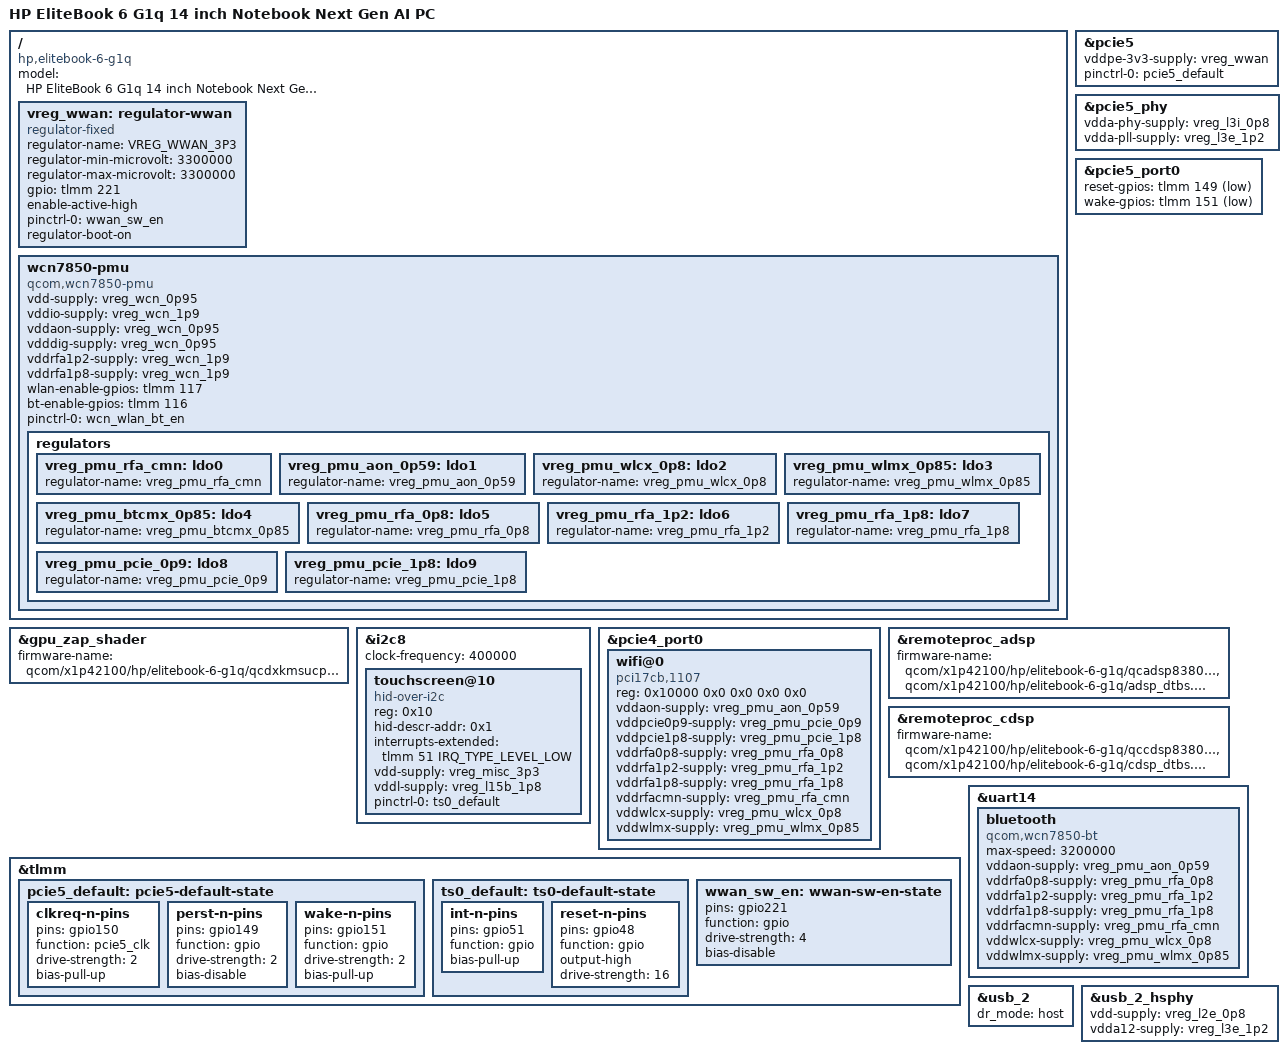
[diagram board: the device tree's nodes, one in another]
// SPDX-License-Identifier: BSD-3-Clause

/dts-v1/;

#include "purwa.dtsi"
#include "hamoa-pmics.dtsi"
#include "x1-hp-elitebook-6-g1q.dtsi"

/delete-node/ &pmc8380_6;
/delete-node/ &pmc8380_6_thermal;
/delete-node/ &pmc8380_6_die_temp;

/ {
	model = "HP EliteBook 6 G1q 14 inch Notebook Next Gen AI PC";
	compatible = "hp,elitebook-6-g1q", "qcom,x1p42100";

	vreg_wwan: regulator-wwan {
		compatible = "regulator-fixed";

		regulator-name = "VREG_WWAN_3P3";
		regulator-min-microvolt = <3300000>;
		regulator-max-microvolt = <3300000>;

		gpio = <&tlmm 221 GPIO_ACTIVE_HIGH>;
		enable-active-high;

		pinctrl-0 = <&wwan_sw_en>;
		pinctrl-names = "default";

		regulator-boot-on;
	};

	wcn7850-pmu {
		compatible = "qcom,wcn7850-pmu";

		vdd-supply = <&vreg_wcn_0p95>;
		vddio-supply = <&vreg_wcn_1p9>;
		vddaon-supply = <&vreg_wcn_0p95>;
		vdddig-supply = <&vreg_wcn_0p95>;
		vddrfa1p2-supply = <&vreg_wcn_1p9>;
		vddrfa1p8-supply = <&vreg_wcn_1p9>;

		wlan-enable-gpios = <&tlmm 117 GPIO_ACTIVE_HIGH>;
		bt-enable-gpios = <&tlmm 116 GPIO_ACTIVE_HIGH>;

		pinctrl-0 = <&wcn_wlan_bt_en>;
		pinctrl-names = "default";

		regulators {
			vreg_pmu_rfa_cmn: ldo0 {
				regulator-name = "vreg_pmu_rfa_cmn";
			};

			vreg_pmu_aon_0p59: ldo1 {
				regulator-name = "vreg_pmu_aon_0p59";
			};

			vreg_pmu_wlcx_0p8: ldo2 {
				regulator-name = "vreg_pmu_wlcx_0p8";
			};

			vreg_pmu_wlmx_0p85: ldo3 {
				regulator-name = "vreg_pmu_wlmx_0p85";
			};

			vreg_pmu_btcmx_0p85: ldo4 {
				regulator-name = "vreg_pmu_btcmx_0p85";
			};

			vreg_pmu_rfa_0p8: ldo5 {
				regulator-name = "vreg_pmu_rfa_0p8";
			};

			vreg_pmu_rfa_1p2: ldo6 {
				regulator-name = "vreg_pmu_rfa_1p2";
			};

			vreg_pmu_rfa_1p8: ldo7 {
				regulator-name = "vreg_pmu_rfa_1p8";
			};

			vreg_pmu_pcie_0p9: ldo8 {
				regulator-name = "vreg_pmu_pcie_0p9";
			};

			vreg_pmu_pcie_1p8: ldo9 {
				regulator-name = "vreg_pmu_pcie_1p8";
			};
		};
	};
};

&gpu_zap_shader {
	firmware-name = "qcom/x1p42100/hp/elitebook-6-g1q/qcdxkmsucpurwa.mbn";
};

&i2c8 {
	clock-frequency = <400000>;

	status = "okay";

	touchscreen@10 {
		compatible = "hid-over-i2c";
		reg = <0x10>;

		hid-descr-addr = <0x1>;
		interrupts-extended = <&tlmm 51 IRQ_TYPE_LEVEL_LOW>;

		vdd-supply = <&vreg_misc_3p3>;
		vddl-supply = <&vreg_l15b_1p8>;

		pinctrl-0 = <&ts0_default>;
		pinctrl-names = "default";
	};
};

&pcie4_port0 {
	wifi@0 {
		compatible = "pci17cb,1107";
		reg = <0x10000 0x0 0x0 0x0 0x0>;

		vddaon-supply = <&vreg_pmu_aon_0p59>;
		vddpcie0p9-supply = <&vreg_pmu_pcie_0p9>;
		vddpcie1p8-supply = <&vreg_pmu_pcie_1p8>;
		vddrfa0p8-supply = <&vreg_pmu_rfa_0p8>;
		vddrfa1p2-supply = <&vreg_pmu_rfa_1p2>;
		vddrfa1p8-supply = <&vreg_pmu_rfa_1p8>;
		vddrfacmn-supply = <&vreg_pmu_rfa_cmn>;
		vddwlcx-supply = <&vreg_pmu_wlcx_0p8>;
		vddwlmx-supply = <&vreg_pmu_wlmx_0p85>;
	};
};

/* Qualcomm Snapdragon X72 5G MHI modem (103c:8e09) */
&pcie5 {
	vddpe-3v3-supply = <&vreg_wwan>;

	pinctrl-0 = <&pcie5_default>;
	pinctrl-names = "default";

	status = "okay";
};

&pcie5_phy {
	vdda-phy-supply = <&vreg_l3i_0p8>;
	vdda-pll-supply = <&vreg_l3e_1p2>;

	status = "okay";
};

&pcie5_port0 {
	reset-gpios = <&tlmm 149 GPIO_ACTIVE_LOW>;
	wake-gpios = <&tlmm 151 GPIO_ACTIVE_LOW>;
};

&remoteproc_adsp {
	firmware-name = "qcom/x1p42100/hp/elitebook-6-g1q/qcadsp8380.mbn",
			"qcom/x1p42100/hp/elitebook-6-g1q/adsp_dtbs.elf";

	status = "okay";
};

&remoteproc_cdsp {
	firmware-name = "qcom/x1p42100/hp/elitebook-6-g1q/qccdsp8380.mbn",
			"qcom/x1p42100/hp/elitebook-6-g1q/cdsp_dtbs.elf";

	status = "okay";
};

&tlmm {
	pcie5_default: pcie5-default-state {
		clkreq-n-pins {
			pins = "gpio150";
			function = "pcie5_clk";
			drive-strength = <2>;
			bias-pull-up;
		};

		perst-n-pins {
			pins = "gpio149";
			function = "gpio";
			drive-strength = <2>;
			bias-disable;
		};

		wake-n-pins {
			pins = "gpio151";
			function = "gpio";
			drive-strength = <2>;
			bias-pull-up;
		};
	};

	ts0_default: ts0-default-state {
		int-n-pins {
			pins = "gpio51";
			function = "gpio";
			bias-pull-up;
		};

		reset-n-pins {
			pins = "gpio48";
			function = "gpio";
			output-high;
			drive-strength = <16>;
		};
	};

	wwan_sw_en: wwan-sw-en-state {
		pins = "gpio221";
		function = "gpio";
		drive-strength = <4>;
		bias-disable;
	};
};

&uart14 {
	status = "okay";

	bluetooth {
		compatible = "qcom,wcn7850-bt";
		max-speed = <3200000>;

		vddaon-supply = <&vreg_pmu_aon_0p59>;
		vddrfa0p8-supply = <&vreg_pmu_rfa_0p8>;
		vddrfa1p2-supply = <&vreg_pmu_rfa_1p2>;
		vddrfa1p8-supply = <&vreg_pmu_rfa_1p8>;
		vddrfacmn-supply = <&vreg_pmu_rfa_cmn>;
		vddwlcx-supply = <&vreg_pmu_wlcx_0p8>;
		vddwlmx-supply = <&vreg_pmu_wlmx_0p85>;
	};
};

/* HP 5MP IR Camera (04f2:b82c) */
&usb_2 {
	dr_mode = "host";

	status = "okay";
};

&usb_2_hsphy {
	vdd-supply = <&vreg_l2e_0p8>;
	vdda12-supply = <&vreg_l3e_1p2>;

	status = "okay";
};
